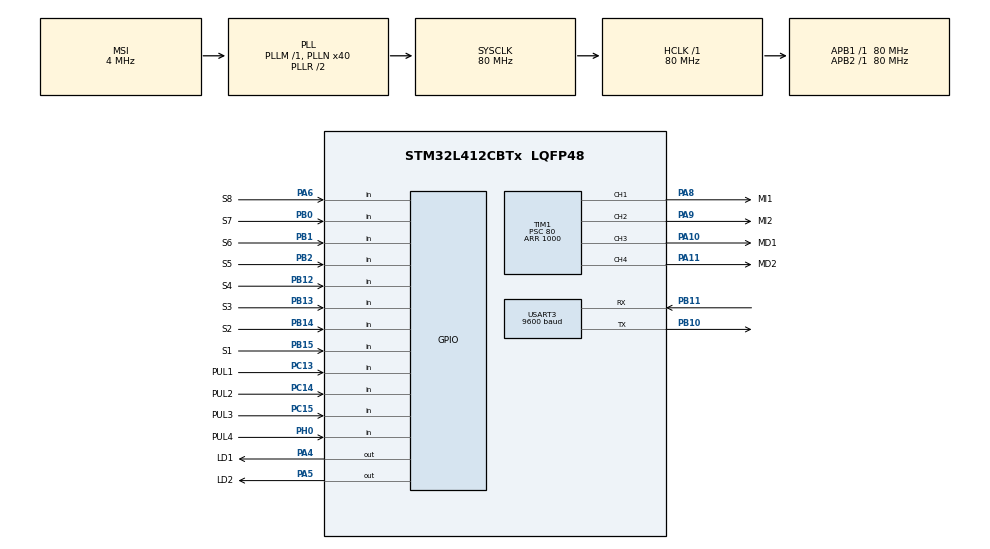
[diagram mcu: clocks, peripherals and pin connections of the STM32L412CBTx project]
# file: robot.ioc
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FREERTOS.Tasks01=tareaControl,0,128,control,As weak,NULL,Dynamic,NULL,NULL;tareaSensores,0,128,sensores,As weak,NULL,Dynamic,NULL,NULL;tareaApi,0,128,api,As weak,NULL,Dynamic,NULL,NULL
Mcu.Family=STM32L4
Mcu.Name=STM32L412CBTx
Mcu.Package=LQFP48
NVIC.PriorityGroup=NVIC_PRIORITYGROUP_4
NVIC.TIM6_IRQn=true\:0\:0\:false\:false\:true\:false\:false\:true
NVIC.TimeBase=TIM6_IRQn
NVIC.TimeBaseIP=TIM6
PA10.GPIO_Label=MD1
PA10.Signal=S_TIM1_CH3
PA11.GPIO_Label=MD2
PA11.Signal=S_TIM1_CH4
PA4.GPIO_Label=LD1
PA4.Signal=GPIO_Output
PA5.GPIO_Label=LD2
PA5.Signal=GPIO_Output
PA6.GPIO_Label=S8
PA6.Signal=GPIO_Input
PA8.GPIO_Label=MI1
PA8.Signal=S_TIM1_CH1
PA9.GPIO_Label=MI2
PA9.Signal=S_TIM1_CH2
PB0.GPIO_Label=S7
PB0.Signal=GPIO_Input
PB1.GPIO_Label=S6
PB1.Signal=GPIO_Input
PB10.Mode=Asynchronous
PB10.Signal=USART3_TX
PB11.Mode=Asynchronous
PB11.Signal=USART3_RX
PB12.GPIO_Label=S4
PB12.Signal=GPIO_Input
PB13.GPIO_Label=S3
PB13.Signal=GPIO_Input
PB14.GPIO_Label=S2
PB14.Signal=GPIO_Input
PB15.GPIO_Label=S1
PB15.Signal=GPIO_Input
PB2.GPIO_Label=S5
PB2.Signal=GPIO_Input
PC13.GPIO_Label=PUL1
PC13.Signal=GPIO_Input
PC14-OSC32_IN\ (PC14).GPIO_Label=PUL2
PC14-OSC32_IN\ (PC14).Signal=GPIO_Input
PC15-OSC32_OUT\ (PC15).GPIO_Label=PUL3
PC15-OSC32_OUT\ (PC15).Signal=GPIO_Input
PH0-OSC_IN\ (PH0).GPIO_Label=PUL4
PH0-OSC_IN\ (PH0).Signal=GPIO_Input
ProjectManager.HeapSize=0x200
ProjectManager.StackSize=0x400
ProjectManager.TargetToolchain=STM32CubeIDE
RCC.ADCFreq_Value=80000000
RCC.AHBFreq_Value=80000000
RCC.APB1Freq_Value=80000000
RCC.APB1TimFreq_Value=80000000
RCC.APB2Freq_Value=80000000
RCC.APB2TimFreq_Value=80000000
RCC.CortexFreq_Value=80000000
RCC.HCLKFreq_Value=80000000
RCC.HSE_VALUE=8000000
RCC.HSI48_VALUE=48000000
RCC.HSI_VALUE=16000000
RCC.LSE_VALUE=32768
RCC.MSI_VALUE=4000000
RCC.PLLN=40
RCC.SYSCLKFreq_VALUE=80000000
RCC.SYSCLKSource=RCC_SYSCLKSOURCE_PLLCLK
RCC.USBFreq_Value=4000000
RCC.VCOOutputFreq_Value=160000000
SH.S_TIM1_CH1.0=TIM1_CH1,PWM Generation1 CH1
SH.S_TIM1_CH2.0=TIM1_CH2,PWM Generation2 CH2
SH.S_TIM1_CH3.0=TIM1_CH3,PWM Generation3 CH3
SH.S_TIM1_CH4.0=TIM1_CH4,PWM Generation4 CH4
TIM1.Channel-PWM\ Generation1\ CH1=TIM_CHANNEL_1
TIM1.Channel-PWM\ Generation2\ CH2=TIM_CHANNEL_2
TIM1.Channel-PWM\ Generation3\ CH3=TIM_CHANNEL_3
TIM1.Channel-PWM\ Generation4\ CH4=TIM_CHANNEL_4
TIM1.Period=1000
TIM1.Prescaler=80
TIM15.Period=1000
TIM15.Prescaler=80
USART3.BaudRate=9600
USART3.VirtualMode-Asynchronous=VM_ASYNC
VP_FREERTOS_VS_CMSIS_V1.Mode=CMSIS_V1
VP_SYS_VS_tim6.Mode=TIM6
VP_TIM15_VS_ClockSourceINT.Mode=Internal
VP_TIM1_VS_ClockSourceINT.Mode=Internal
board=custom

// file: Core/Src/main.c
/* USER CODE BEGIN Header */
/**
  ******************************************************************************
  * @file           : main.c
  * @brief          : Main program body
  ******************************************************************************
  * @attention
  *
  * <h2><center>&copy; Copyright (c) 2020 STMicroelectronics.
  * All rights reserved.</center></h2>
  *
  * This software component is licensed by ST under BSD 3-Clause license,
  * the "License"; You may not use this file except in compliance with the
  * License. You may obtain a copy of the License at:
  *                        opensource.org/licenses/BSD-3-Clause
  *
  ******************************************************************************
  */
/* USER CODE END Header */

#include "main.h"
#include "cmsis_os.h"

/* USER CODE BEGIN Includes */
#include "control.h"
#include "leds.h"
/* USER CODE END Includes */

TIM_HandleTypeDef htim1;
TIM_HandleTypeDef htim15;

UART_HandleTypeDef huart3;

osThreadId tareaControlHandle;
osThreadId tareaSensoresHandle;
osThreadId tareaApiHandle;

void SystemClock_Config(void);
static void MX_GPIO_Init(void);static void MX_TIM1_Init(void);
static void MX_TIM15_Init(void);
static void MX_USART3_UART_Init(void);
void control(void const * argument);
void sensores(void const * argument);
void api(void const * argument);

int main(void)
{

  /* MCU Configuration--------------------------------------------------------*/

  /* Reset of all peripherals, Initializes the Flash interface and the Systick. */
  HAL_Init();

  /* Configure the system clock */
  SystemClock_Config();

  /* Initialize all configured peripherals */
  MX_GPIO_Init();
  MX_TIM1_Init();
  MX_TIM15_Init();
  MX_USART3_UART_Init();

  /* Create the thread(s) */
  /* definition and creation of tareaControl */
  osThreadDef(tareaControl, control, osPriorityNormal, 0, 128);
  tareaControlHandle = osThreadCreate(osThread(tareaControl), NULL);

  /* definition and creation of tareaSensores */
  osThreadDef(tareaSensores, sensores, osPriorityNormal, 0, 128);
  tareaSensoresHandle = osThreadCreate(osThread(tareaSensores), NULL);

  /* definition and creation of tareaApi */
  osThreadDef(tareaApi, api, osPriorityNormal, 0, 128);
  tareaApiHandle = osThreadCreate(osThread(tareaApi), NULL);

  /* Start scheduler */
  osKernelStart();

  /* We should never get here as control is now taken by the scheduler */
  /* Infinite loop */
  while (1)
  {

  }
}

void SystemClock_Config(void)
{
  RCC_OscInitTypeDef RCC_OscInitStruct = {0};
  RCC_ClkInitTypeDef RCC_ClkInitStruct = {0};
  RCC_PeriphCLKInitTypeDef PeriphClkInit = {0};

  /** Configure the main internal regulator output voltage
  */
  if (HAL_PWREx_ControlVoltageScaling(PWR_REGULATOR_VOLTAGE_SCALE1) != HAL_OK)
  {
    Error_Handler();
  }
  /** Initializes the CPU, AHB and APB busses clocks
  */
  RCC_OscInitStruct.OscillatorType = RCC_OSCILLATORTYPE_MSI;
  RCC_OscInitStruct.MSIState = RCC_MSI_ON;
  RCC_OscInitStruct.MSICalibrationValue = 0;
  RCC_OscInitStruct.MSIClockRange = RCC_MSIRANGE_6;
  RCC_OscInitStruct.PLL.PLLState = RCC_PLL_ON;
  RCC_OscInitStruct.PLL.PLLSource = RCC_PLLSOURCE_MSI;
  RCC_OscInitStruct.PLL.PLLM = 1;
  RCC_OscInitStruct.PLL.PLLN = 40;
  RCC_OscInitStruct.PLL.PLLQ = RCC_PLLQ_DIV2;
  RCC_OscInitStruct.PLL.PLLR = RCC_PLLR_DIV2;
  if (HAL_RCC_OscConfig(&RCC_OscInitStruct) != HAL_OK)
  {
    Error_Handler();
  }
  /** Initializes the CPU, AHB and APB busses clocks
  */
  RCC_ClkInitStruct.ClockType = RCC_CLOCKTYPE_HCLK|RCC_CLOCKTYPE_SYSCLK
                              |RCC_CLOCKTYPE_PCLK1|RCC_CLOCKTYPE_PCLK2;
  RCC_ClkInitStruct.SYSCLKSource = RCC_SYSCLKSOURCE_PLLCLK;
  RCC_ClkInitStruct.AHBCLKDivider = RCC_SYSCLK_DIV1;
  RCC_ClkInitStruct.APB1CLKDivider = RCC_HCLK_DIV1;
  RCC_ClkInitStruct.APB2CLKDivider = RCC_HCLK_DIV1;

  if (HAL_RCC_ClockConfig(&RCC_ClkInitStruct, FLASH_LATENCY_4) != HAL_OK)
  {
    Error_Handler();
  }
  PeriphClkInit.PeriphClockSelection = RCC_PERIPHCLK_USART3;
  PeriphClkInit.Usart3ClockSelection = RCC_USART3CLKSOURCE_PCLK1;
  if (HAL_RCCEx_PeriphCLKConfig(&PeriphClkInit) != HAL_OK)
  {
    Error_Handler();
  }
}

static void MX_TIM1_Init(void)
{

  TIM_ClockConfigTypeDef sClockSourceConfig = {0};
  TIM_MasterConfigTypeDef sMasterConfig = {0};
  TIM_OC_InitTypeDef sConfigOC = {0};
  TIM_BreakDeadTimeConfigTypeDef sBreakDeadTimeConfig = {0};

  htim1.Instance = TIM1;
  htim1.Init.Prescaler = 80;
  htim1.Init.CounterMode = TIM_COUNTERMODE_UP;
  htim1.Init.Period = 1000;
  htim1.Init.ClockDivision = TIM_CLOCKDIVISION_DIV1;
  htim1.Init.RepetitionCounter = 0;
  htim1.Init.AutoReloadPreload = TIM_AUTORELOAD_PRELOAD_DISABLE;
  if (HAL_TIM_Base_Init(&htim1) != HAL_OK)
  {
    Error_Handler();
  }
  sClockSourceConfig.ClockSource = TIM_CLOCKSOURCE_INTERNAL;
  if (HAL_TIM_ConfigClockSource(&htim1, &sClockSourceConfig) != HAL_OK)
  {
    Error_Handler();
  }
  if (HAL_TIM_PWM_Init(&htim1) != HAL_OK)
  {
    Error_Handler();
  }
  sMasterConfig.MasterOutputTrigger = TIM_TRGO_RESET;
  sMasterConfig.MasterOutputTrigger2 = TIM_TRGO2_RESET;
  sMasterConfig.MasterSlaveMode = TIM_MASTERSLAVEMODE_DISABLE;
  if (HAL_TIMEx_MasterConfigSynchronization(&htim1, &sMasterConfig) != HAL_OK)
  {
    Error_Handler();
  }
  sConfigOC.OCMode = TIM_OCMODE_PWM1;
  sConfigOC.Pulse = 0;
  sConfigOC.OCPolarity = TIM_OCPOLARITY_HIGH;
  sConfigOC.OCNPolarity = TIM_OCNPOLARITY_HIGH;
  sConfigOC.OCFastMode = TIM_OCFAST_DISABLE;
  sConfigOC.OCIdleState = TIM_OCIDLESTATE_RESET;
  sConfigOC.OCNIdleState = TIM_OCNIDLESTATE_RESET;
  if (HAL_TIM_PWM_ConfigChannel(&htim1, &sConfigOC, TIM_CHANNEL_1) != HAL_OK)
  {
    Error_Handler();
  }
  if (HAL_TIM_PWM_ConfigChannel(&htim1, &sConfigOC, TIM_CHANNEL_2) != HAL_OK)
  {
    Error_Handler();
  }
  if (HAL_TIM_PWM_ConfigChannel(&htim1, &sConfigOC, TIM_CHANNEL_3) != HAL_OK)
  {
    Error_Handler();
  }
  if (HAL_TIM_PWM_ConfigChannel(&htim1, &sConfigOC, TIM_CHANNEL_4) != HAL_OK)
  {
    Error_Handler();
  }
  sBreakDeadTimeConfig.OffStateRunMode = TIM_OSSR_DISABLE;
  sBreakDeadTimeConfig.OffStateIDLEMode = TIM_OSSI_DISABLE;
  sBreakDeadTimeConfig.LockLevel = TIM_LOCKLEVEL_OFF;
  sBreakDeadTimeConfig.DeadTime = 0;
  sBreakDeadTimeConfig.BreakState = TIM_BREAK_DISABLE;
  sBreakDeadTimeConfig.BreakPolarity = TIM_BREAKPOLARITY_HIGH;
  sBreakDeadTimeConfig.BreakFilter = 0;
  sBreakDeadTimeConfig.Break2State = TIM_BREAK2_DISABLE;
  sBreakDeadTimeConfig.Break2Polarity = TIM_BREAK2POLARITY_HIGH;
  sBreakDeadTimeConfig.Break2Filter = 0;
  sBreakDeadTimeConfig.AutomaticOutput = TIM_AUTOMATICOUTPUT_DISABLE;
  if (HAL_TIMEx_ConfigBreakDeadTime(&htim1, &sBreakDeadTimeConfig) != HAL_OK)
  {
    Error_Handler();
  }
  HAL_TIM_MspPostInit(&htim1);

}

static void MX_TIM15_Init(void)
{

  TIM_ClockConfigTypeDef sClockSourceConfig = {0};
  TIM_MasterConfigTypeDef sMasterConfig = {0};

  htim15.Instance = TIM15;
  htim15.Init.Prescaler = 80;
  htim15.Init.CounterMode = TIM_COUNTERMODE_UP;
  htim15.Init.Period = 1000;
  htim15.Init.ClockDivision = TIM_CLOCKDIVISION_DIV1;
  htim15.Init.RepetitionCounter = 0;
  htim15.Init.AutoReloadPreload = TIM_AUTORELOAD_PRELOAD_DISABLE;
  if (HAL_TIM_Base_Init(&htim15) != HAL_OK)
  {
    Error_Handler();
  }
  sClockSourceConfig.ClockSource = TIM_CLOCKSOURCE_INTERNAL;
  if (HAL_TIM_ConfigClockSource(&htim15, &sClockSourceConfig) != HAL_OK)
  {
    Error_Handler();
  }
  sMasterConfig.MasterOutputTrigger = TIM_TRGO_RESET;
  sMasterConfig.MasterSlaveMode = TIM_MASTERSLAVEMODE_DISABLE;
  if (HAL_TIMEx_MasterConfigSynchronization(&htim15, &sMasterConfig) != HAL_OK)
  {
    Error_Handler();
  }

}

static void MX_USART3_UART_Init(void)
{

  huart3.Instance = USART3;
  huart3.Init.BaudRate = 9600;
  huart3.Init.WordLength = UART_WORDLENGTH_8B;
  huart3.Init.StopBits = UART_STOPBITS_1;
  huart3.Init.Parity = UART_PARITY_NONE;
  huart3.Init.Mode = UART_MODE_TX_RX;
  huart3.Init.HwFlowCtl = UART_HWCONTROL_NONE;
  huart3.Init.OverSampling = UART_OVERSAMPLING_16;
  huart3.Init.OneBitSampling = UART_ONE_BIT_SAMPLE_DISABLE;
  huart3.AdvancedInit.AdvFeatureInit = UART_ADVFEATURE_NO_INIT;
  if (HAL_UART_Init(&huart3) != HAL_OK)
  {
    Error_Handler();
  }

}

static void MX_GPIO_Init(void)
{
  GPIO_InitTypeDef GPIO_InitStruct = {0};

  /* GPIO Ports Clock Enable */
  __HAL_RCC_GPIOC_CLK_ENABLE();
  __HAL_RCC_GPIOH_CLK_ENABLE();
  __HAL_RCC_GPIOA_CLK_ENABLE();
  __HAL_RCC_GPIOB_CLK_ENABLE();

  /*Configure GPIO pin Output Level */
  HAL_GPIO_WritePin(GPIOA, LD1_Pin|LD2_Pin, GPIO_PIN_RESET);

  /*Configure GPIO pins : PUL1_Pin PUL2_Pin PUL3_Pin */
  GPIO_InitStruct.Pin = PUL1_Pin|PUL2_Pin|PUL3_Pin;
  GPIO_InitStruct.Mode = GPIO_MODE_INPUT;
  GPIO_InitStruct.Pull = GPIO_NOPULL;
  HAL_GPIO_Init(GPIOC, &GPIO_InitStruct);

  /*Configure GPIO pin : PUL4_Pin */
  GPIO_InitStruct.Pin = PUL4_Pin;
  GPIO_InitStruct.Mode = GPIO_MODE_INPUT;
  GPIO_InitStruct.Pull = GPIO_NOPULL;
  HAL_GPIO_Init(PUL4_GPIO_Port, &GPIO_InitStruct);

  /*Configure GPIO pins : LD1_Pin LD2_Pin */
  GPIO_InitStruct.Pin = LD1_Pin|LD2_Pin;
  GPIO_InitStruct.Mode = GPIO_MODE_OUTPUT_PP;
  GPIO_InitStruct.Pull = GPIO_NOPULL;
  GPIO_InitStruct.Speed = GPIO_SPEED_FREQ_LOW;
  HAL_GPIO_Init(GPIOA, &GPIO_InitStruct);

  /*Configure GPIO pin : S8_Pin */
  GPIO_InitStruct.Pin = S8_Pin;
  GPIO_InitStruct.Mode = GPIO_MODE_INPUT;
  GPIO_InitStruct.Pull = GPIO_NOPULL;
  HAL_GPIO_Init(S8_GPIO_Port, &GPIO_InitStruct);

  /*Configure GPIO pins : S7_Pin S6_Pin S5_Pin S4_Pin
                           S3_Pin S2_Pin S1_Pin */
  GPIO_InitStruct.Pin = S7_Pin|S6_Pin|S5_Pin|S4_Pin
                          |S3_Pin|S2_Pin|S1_Pin;
  GPIO_InitStruct.Mode = GPIO_MODE_INPUT;
  GPIO_InitStruct.Pull = GPIO_NOPULL;
  HAL_GPIO_Init(GPIOB, &GPIO_InitStruct);

}

__weak void control(void const * argument)
{
  for(;;)
  {
    osDelay(1);
  }
}

__weak void sensores(void const * argument)
{
  for(;;)
  {
    osDelay(1);
  }
}

__weak void api(void const * argument)
{
  for(;;)
  {
    osDelay(1);
  }
}

 /**
  * @brief  Period elapsed callback in non blocking mode
  * @note   This function is called  when TIM6 interrupt took place, inside
  * HAL_TIM_IRQHandler(). It makes a direct call to HAL_IncTick() to increment
  * a global variable "uwTick" used as application time base.
  * @param  htim : TIM handle
  * @retval None
  */
void HAL_TIM_PeriodElapsedCallback(TIM_HandleTypeDef *htim)
{
  if (htim->Instance == TIM6) {
    HAL_IncTick();
  }
}

void Error_Handler(void)
{
}

/************************ (C) COPYRIGHT STMicroelectronics *****END OF FILE****/
